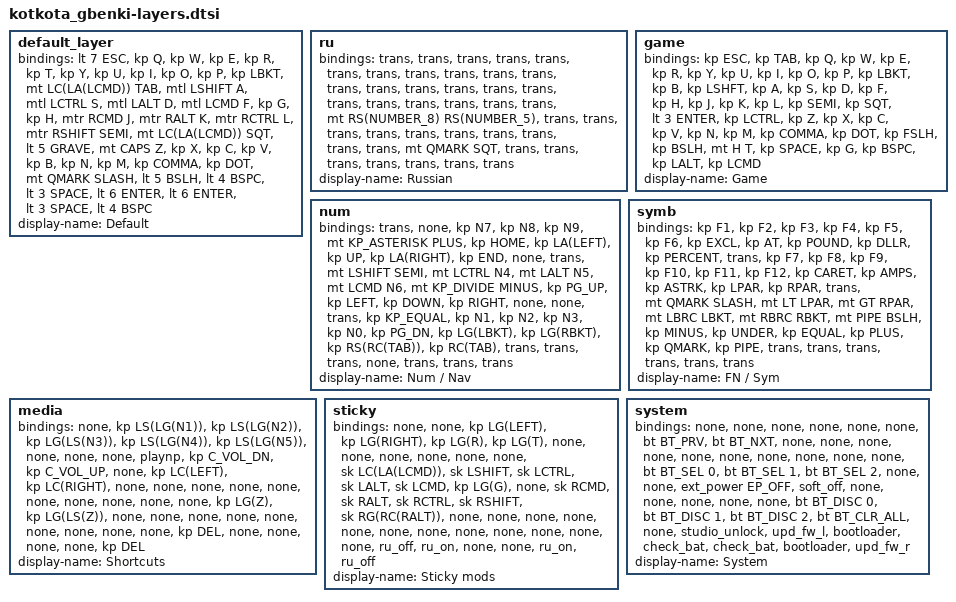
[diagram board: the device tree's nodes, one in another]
default_layer {
  bindings = <
    &lt 7 ESC             &kp Q          &kp W         &kp E        &kp R        &kp T          &kp Y        &kp U        &kp I        &kp O         &kp P             &kp LBKT
    &mt LC(LA(LCMD)) TAB  &mtl LSHIFT A  &mtl LCTRL S  &mtl LALT D  &mtl LCMD F  &kp G          &kp H        &mtr RCMD J  &mtr RALT K  &mtr RCTRL L  &mtr RSHIFT SEMI  &mt LC(LA(LCMD)) SQT
    &lt 5 GRAVE           &mt CAPS Z     &kp X         &kp C        &kp V        &kp B          &kp N        &kp M        &kp COMMA    &kp DOT    &mt QMARK SLASH   &lt 5 BSLH
                                              &lt 4 BSPC   &lt 3 SPACE  &lt 6 ENTER    &lt 6 ENTER  &lt 3 SPACE  &lt 4 BSPC
  >;

  display-name = "Default";
};

ru {
  bindings = <
  &trans  &trans  &trans  &trans  &trans  &trans    &trans  &trans  &trans  &trans  &trans         &trans
  &trans  &trans  &trans  &trans  &trans  &trans    &trans  &trans  &trans  &trans  &trans         &mt RS(NUMBER_8) RS(NUMBER_5)
  &trans  &trans  &trans  &trans  &trans  &trans    &trans  &trans  &trans  &trans  &mt QMARK SQT  &trans
                &trans  &trans  &trans    &trans  &trans  &trans
  >;

  display-name = "Russian";
};

game {
  bindings = <
  &kp ESC      &kp TAB    &kp Q  &kp W    &kp E      &kp R    &kp Y     &kp U     &kp I      &kp O    &kp P     &kp LBKT
  &kp B        &kp LSHFT  &kp A  &kp S    &kp D      &kp F    &kp H     &kp J     &kp K      &kp L    &kp SEMI  &kp SQT
  &lt 3 ENTER  &kp LCTRL  &kp Z  &kp X    &kp C      &kp V    &kp N     &kp M     &kp COMMA  &kp DOT  &kp FSLH  &kp BSLH
                        &mt H T  &kp SPACE  &kp G    &kp BSPC  &kp LALT  &kp LCMD
  >;

  display-name = "Game";
};

num {
  bindings = <
  &trans  &none            &kp N7        &kp N8       &kp N9       &mt KP_ASTERISK PLUS    &kp HOME   &kp LA(LEFT)  &kp UP        &kp LA(RIGHT)    &kp END      &none
  &trans  &mt LSHIFT SEMI  &mt LCTRL N4  &mt LALT N5  &mt LCMD N6  &mt KP_DIVIDE MINUS     &kp PG_UP  &kp LEFT      &kp DOWN      &kp RIGHT        &none        &none
  &trans  &kp KP_EQUAL     &kp N1        &kp N2       &kp N3       &kp N0                  &kp PG_DN  &kp LG(LBKT)  &kp LG(RBKT)  &kp RS(RC(TAB))  &kp RC(TAB)  &trans
                                &trans       &trans       &none                   &trans     &trans        &trans
  >;

  display-name = "Num / Nav";
};

symb {
  bindings = <
  &kp F1           &kp F2       &kp F3       &kp F4         &kp F5         &kp F6           &kp EXCL   &kp AT     &kp POUND  &kp DLLR  &kp PERCENT  &trans
  &kp F7           &kp F8       &kp F9       &kp F10        &kp F11        &kp F12          &kp CARET  &kp AMPS   &kp ASTRK  &kp LPAR  &kp RPAR     &trans
  &mt QMARK SLASH  &mt LT LPAR  &mt GT RPAR  &mt LBRC LBKT  &mt RBRC RBKT  &mt PIPE BSLH    &kp MINUS  &kp UNDER  &kp EQUAL  &kp PLUS  &kp QMARK    &kp PIPE
                                    &trans         &trans         &trans           &trans     &trans     &trans
  >;

  display-name = "FN / Sym";
};

media {
  bindings = <
  &none  &kp LS(LG(N1))  &kp LS(LG(N2))  &kp LG(LS(N3))  &kp LS(LG(N4))  &kp LS(LG(N5))    &none  &none  &none    &playnp  &kp C_VOL_DN  &kp C_VOL_UP
  &none  &kp LC(LEFT)    &kp LC(RIGHT)   &none           &none           &none             &none  &none  &none    &none    &none         &none
  &none  &kp LG(Z)       &kp LG(LS(Z))   &none           &none           &none             &none  &none  &none    &none    &none         &none
                                &kp DEL         &none           &none             &none  &none  &kp DEL
  >;

  display-name = "Shortcuts";
};

sticky {
  bindings = <
  &none             &none       &kp LG(LEFT)  &kp LG(RIGHT)  &kp LG(R)  &kp LG(T)    &none  &none     &none     &none      &none       &none
  &sk LC(LA(LCMD))  &sk LSHIFT  &sk LCTRL     &sk LALT       &sk LCMD   &kp LG(G)    &none  &sk RCMD  &sk RALT  &sk RCTRL  &sk RSHIFT  &sk RG(RC(RALT))
  &none             &none       &none         &none          &none      &none        &none  &none     &none     &none      &none       &none
                                    &ru_off        &ru_on     &none        &none  &ru_on    &ru_off
  >;

  display-name = "Sticky mods";
};

system {
  bindings = <
  &none      &none  &none  &none      &none        &none         &bt BT_PRV     &bt BT_NXT     &none          &none           &none  &none
  &none      &none  &none  &none      &none        &none         &bt BT_SEL 0   &bt BT_SEL 1   &bt BT_SEL 2   &none           &none  &ext_power EP_OFF
  &soft_off  &none  &none  &none      &none        &none         &bt BT_DISC 0  &bt BT_DISC 1  &bt BT_DISC 2  &bt BT_CLR_ALL  &none  &studio_unlock
                  &upd_fw_l  &bootloader  &check_bat    &check_bat     &bootloader    &upd_fw_r
  >;

  display-name = "System";
};
